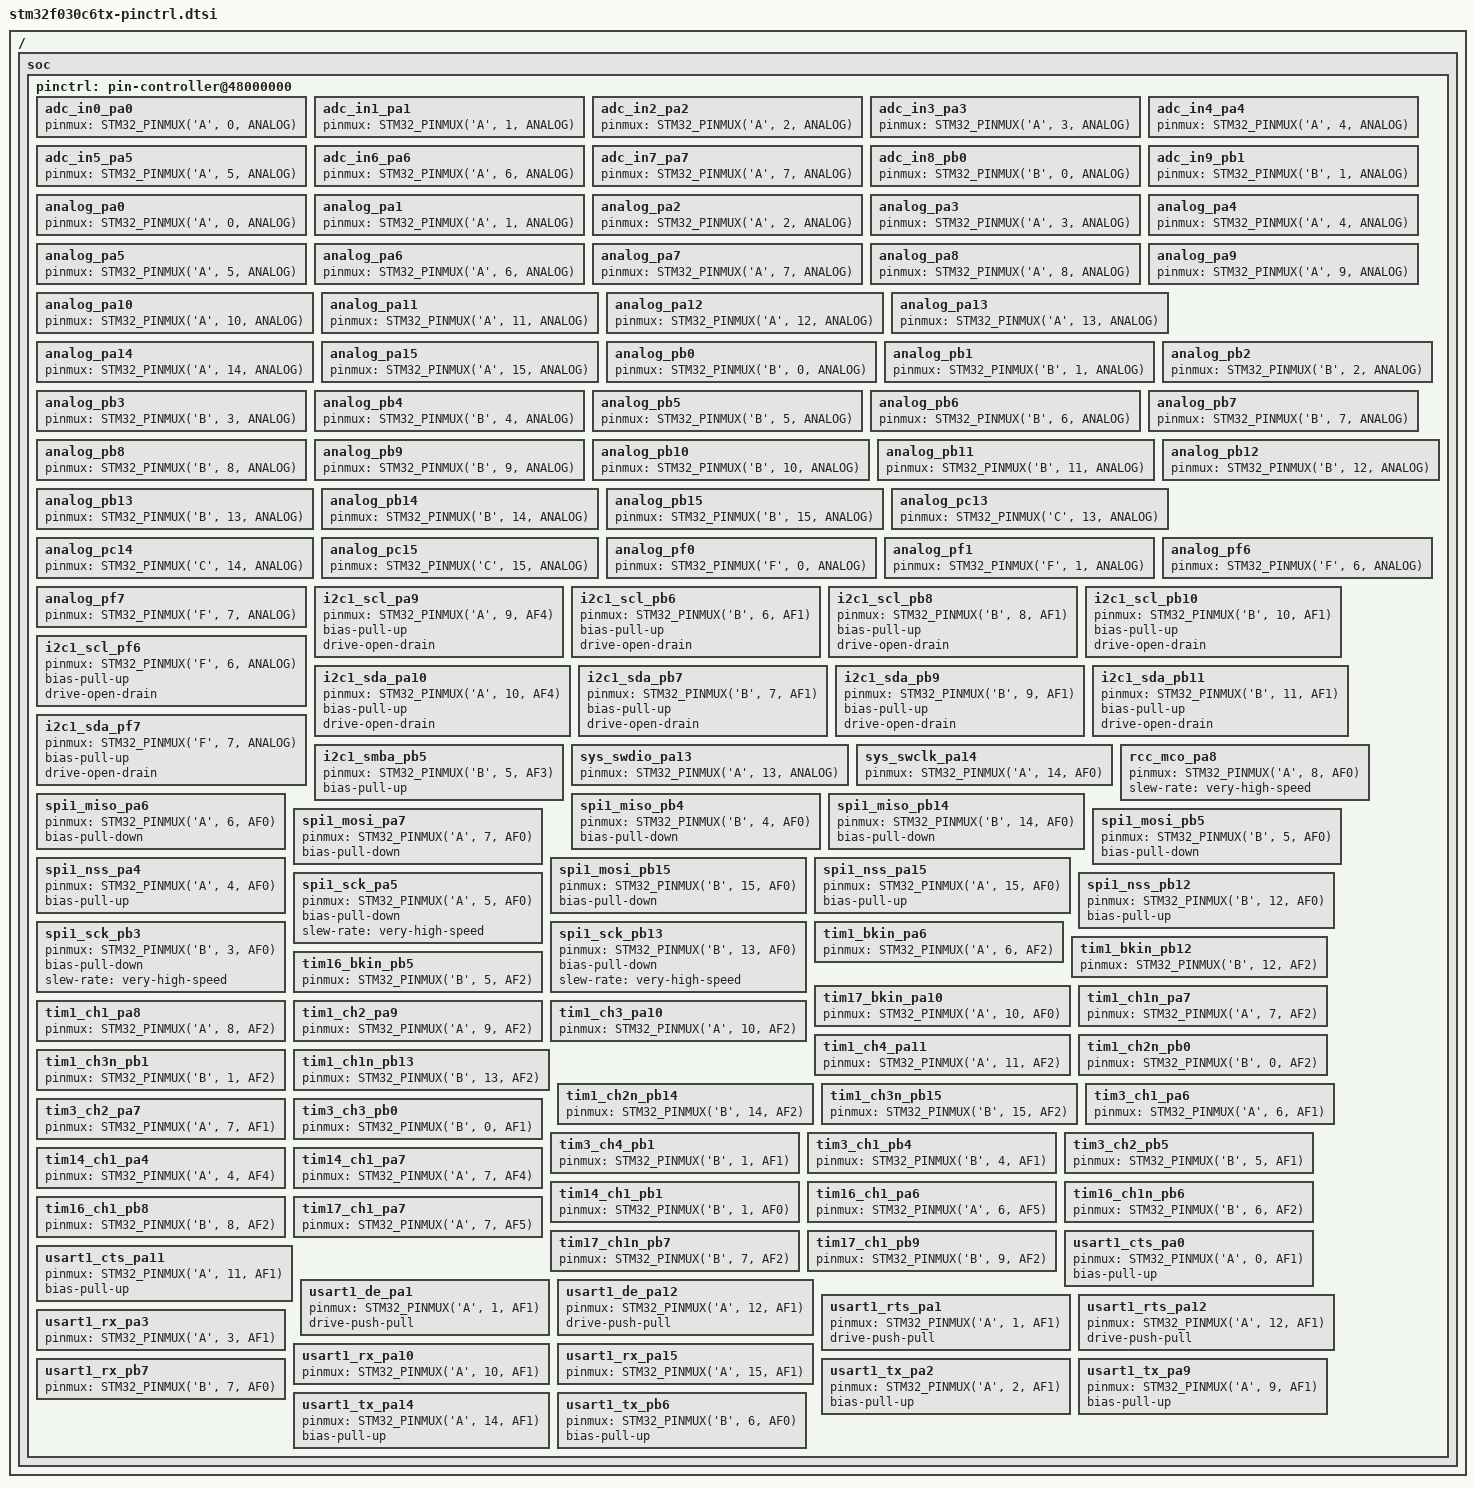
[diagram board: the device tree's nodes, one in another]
/*
 * NOTE: Autogenerated file using genpinctrl.py
 *
 * SPDX-License-Identifier: Apache-2.0
 */

#include <zephyr/dt-bindings/pinctrl/stm32-pinctrl.h>

/ {
	soc {
		pinctrl: pin-controller@48000000 {

			/* ADC_IN / ADC_INN / ADC_INP */

			/omit-if-no-ref/ adc_in0_pa0: adc_in0_pa0 {
				pinmux = <STM32_PINMUX('A', 0, ANALOG)>;
			};

			/omit-if-no-ref/ adc_in1_pa1: adc_in1_pa1 {
				pinmux = <STM32_PINMUX('A', 1, ANALOG)>;
			};

			/omit-if-no-ref/ adc_in2_pa2: adc_in2_pa2 {
				pinmux = <STM32_PINMUX('A', 2, ANALOG)>;
			};

			/omit-if-no-ref/ adc_in3_pa3: adc_in3_pa3 {
				pinmux = <STM32_PINMUX('A', 3, ANALOG)>;
			};

			/omit-if-no-ref/ adc_in4_pa4: adc_in4_pa4 {
				pinmux = <STM32_PINMUX('A', 4, ANALOG)>;
			};

			/omit-if-no-ref/ adc_in5_pa5: adc_in5_pa5 {
				pinmux = <STM32_PINMUX('A', 5, ANALOG)>;
			};

			/omit-if-no-ref/ adc_in6_pa6: adc_in6_pa6 {
				pinmux = <STM32_PINMUX('A', 6, ANALOG)>;
			};

			/omit-if-no-ref/ adc_in7_pa7: adc_in7_pa7 {
				pinmux = <STM32_PINMUX('A', 7, ANALOG)>;
			};

			/omit-if-no-ref/ adc_in8_pb0: adc_in8_pb0 {
				pinmux = <STM32_PINMUX('B', 0, ANALOG)>;
			};

			/omit-if-no-ref/ adc_in9_pb1: adc_in9_pb1 {
				pinmux = <STM32_PINMUX('B', 1, ANALOG)>;
			};

			/* Analog */

			/omit-if-no-ref/ analog_pa0: analog_pa0 {
				pinmux = <STM32_PINMUX('A', 0, ANALOG)>;
			};

			/omit-if-no-ref/ analog_pa1: analog_pa1 {
				pinmux = <STM32_PINMUX('A', 1, ANALOG)>;
			};

			/omit-if-no-ref/ analog_pa2: analog_pa2 {
				pinmux = <STM32_PINMUX('A', 2, ANALOG)>;
			};

			/omit-if-no-ref/ analog_pa3: analog_pa3 {
				pinmux = <STM32_PINMUX('A', 3, ANALOG)>;
			};

			/omit-if-no-ref/ analog_pa4: analog_pa4 {
				pinmux = <STM32_PINMUX('A', 4, ANALOG)>;
			};

			/omit-if-no-ref/ analog_pa5: analog_pa5 {
				pinmux = <STM32_PINMUX('A', 5, ANALOG)>;
			};

			/omit-if-no-ref/ analog_pa6: analog_pa6 {
				pinmux = <STM32_PINMUX('A', 6, ANALOG)>;
			};

			/omit-if-no-ref/ analog_pa7: analog_pa7 {
				pinmux = <STM32_PINMUX('A', 7, ANALOG)>;
			};

			/omit-if-no-ref/ analog_pa8: analog_pa8 {
				pinmux = <STM32_PINMUX('A', 8, ANALOG)>;
			};

			/omit-if-no-ref/ analog_pa9: analog_pa9 {
				pinmux = <STM32_PINMUX('A', 9, ANALOG)>;
			};

			/omit-if-no-ref/ analog_pa10: analog_pa10 {
				pinmux = <STM32_PINMUX('A', 10, ANALOG)>;
			};

			/omit-if-no-ref/ analog_pa11: analog_pa11 {
				pinmux = <STM32_PINMUX('A', 11, ANALOG)>;
			};

			/omit-if-no-ref/ analog_pa12: analog_pa12 {
				pinmux = <STM32_PINMUX('A', 12, ANALOG)>;
			};

			/omit-if-no-ref/ analog_pa13: analog_pa13 {
				pinmux = <STM32_PINMUX('A', 13, ANALOG)>;
			};

			/omit-if-no-ref/ analog_pa14: analog_pa14 {
				pinmux = <STM32_PINMUX('A', 14, ANALOG)>;
			};

			/omit-if-no-ref/ analog_pa15: analog_pa15 {
				pinmux = <STM32_PINMUX('A', 15, ANALOG)>;
			};

			/omit-if-no-ref/ analog_pb0: analog_pb0 {
				pinmux = <STM32_PINMUX('B', 0, ANALOG)>;
			};

			/omit-if-no-ref/ analog_pb1: analog_pb1 {
				pinmux = <STM32_PINMUX('B', 1, ANALOG)>;
			};

			/omit-if-no-ref/ analog_pb2: analog_pb2 {
				pinmux = <STM32_PINMUX('B', 2, ANALOG)>;
			};

			/omit-if-no-ref/ analog_pb3: analog_pb3 {
				pinmux = <STM32_PINMUX('B', 3, ANALOG)>;
			};

			/omit-if-no-ref/ analog_pb4: analog_pb4 {
				pinmux = <STM32_PINMUX('B', 4, ANALOG)>;
			};

			/omit-if-no-ref/ analog_pb5: analog_pb5 {
				pinmux = <STM32_PINMUX('B', 5, ANALOG)>;
			};

			/omit-if-no-ref/ analog_pb6: analog_pb6 {
				pinmux = <STM32_PINMUX('B', 6, ANALOG)>;
			};

			/omit-if-no-ref/ analog_pb7: analog_pb7 {
				pinmux = <STM32_PINMUX('B', 7, ANALOG)>;
			};

			/omit-if-no-ref/ analog_pb8: analog_pb8 {
				pinmux = <STM32_PINMUX('B', 8, ANALOG)>;
			};

			/omit-if-no-ref/ analog_pb9: analog_pb9 {
				pinmux = <STM32_PINMUX('B', 9, ANALOG)>;
			};

			/omit-if-no-ref/ analog_pb10: analog_pb10 {
				pinmux = <STM32_PINMUX('B', 10, ANALOG)>;
			};

			/omit-if-no-ref/ analog_pb11: analog_pb11 {
				pinmux = <STM32_PINMUX('B', 11, ANALOG)>;
			};

			/omit-if-no-ref/ analog_pb12: analog_pb12 {
				pinmux = <STM32_PINMUX('B', 12, ANALOG)>;
			};

			/omit-if-no-ref/ analog_pb13: analog_pb13 {
				pinmux = <STM32_PINMUX('B', 13, ANALOG)>;
			};

			/omit-if-no-ref/ analog_pb14: analog_pb14 {
				pinmux = <STM32_PINMUX('B', 14, ANALOG)>;
			};

			/omit-if-no-ref/ analog_pb15: analog_pb15 {
				pinmux = <STM32_PINMUX('B', 15, ANALOG)>;
			};

			/omit-if-no-ref/ analog_pc13: analog_pc13 {
				pinmux = <STM32_PINMUX('C', 13, ANALOG)>;
			};

			/omit-if-no-ref/ analog_pc14: analog_pc14 {
				pinmux = <STM32_PINMUX('C', 14, ANALOG)>;
			};

			/omit-if-no-ref/ analog_pc15: analog_pc15 {
				pinmux = <STM32_PINMUX('C', 15, ANALOG)>;
			};

			/omit-if-no-ref/ analog_pf0: analog_pf0 {
				pinmux = <STM32_PINMUX('F', 0, ANALOG)>;
			};

			/omit-if-no-ref/ analog_pf1: analog_pf1 {
				pinmux = <STM32_PINMUX('F', 1, ANALOG)>;
			};

			/omit-if-no-ref/ analog_pf6: analog_pf6 {
				pinmux = <STM32_PINMUX('F', 6, ANALOG)>;
			};

			/omit-if-no-ref/ analog_pf7: analog_pf7 {
				pinmux = <STM32_PINMUX('F', 7, ANALOG)>;
			};

			/* I2C_SCL */

			/omit-if-no-ref/ i2c1_scl_pa9: i2c1_scl_pa9 {
				pinmux = <STM32_PINMUX('A', 9, AF4)>;
				bias-pull-up;
				drive-open-drain;
			};

			/omit-if-no-ref/ i2c1_scl_pb6: i2c1_scl_pb6 {
				pinmux = <STM32_PINMUX('B', 6, AF1)>;
				bias-pull-up;
				drive-open-drain;
			};

			/omit-if-no-ref/ i2c1_scl_pb8: i2c1_scl_pb8 {
				pinmux = <STM32_PINMUX('B', 8, AF1)>;
				bias-pull-up;
				drive-open-drain;
			};

			/omit-if-no-ref/ i2c1_scl_pb10: i2c1_scl_pb10 {
				pinmux = <STM32_PINMUX('B', 10, AF1)>;
				bias-pull-up;
				drive-open-drain;
			};

			/omit-if-no-ref/ i2c1_scl_pf6: i2c1_scl_pf6 {
				pinmux = <STM32_PINMUX('F', 6, ANALOG)>;
				bias-pull-up;
				drive-open-drain;
			};

			/* I2C_SDA */

			/omit-if-no-ref/ i2c1_sda_pa10: i2c1_sda_pa10 {
				pinmux = <STM32_PINMUX('A', 10, AF4)>;
				bias-pull-up;
				drive-open-drain;
			};

			/omit-if-no-ref/ i2c1_sda_pb7: i2c1_sda_pb7 {
				pinmux = <STM32_PINMUX('B', 7, AF1)>;
				bias-pull-up;
				drive-open-drain;
			};

			/omit-if-no-ref/ i2c1_sda_pb9: i2c1_sda_pb9 {
				pinmux = <STM32_PINMUX('B', 9, AF1)>;
				bias-pull-up;
				drive-open-drain;
			};

			/omit-if-no-ref/ i2c1_sda_pb11: i2c1_sda_pb11 {
				pinmux = <STM32_PINMUX('B', 11, AF1)>;
				bias-pull-up;
				drive-open-drain;
			};

			/omit-if-no-ref/ i2c1_sda_pf7: i2c1_sda_pf7 {
				pinmux = <STM32_PINMUX('F', 7, ANALOG)>;
				bias-pull-up;
				drive-open-drain;
			};

			/* I2C_SMBA */

			/omit-if-no-ref/ i2c1_smba_pb5: i2c1_smba_pb5 {
				pinmux = <STM32_PINMUX('B', 5, AF3)>;
				bias-pull-up;
			};

			/* JTAG PORT */

			/omit-if-no-ref/ sys_swdio_pa13: sys_swdio_pa13 {
				pinmux = <STM32_PINMUX('A', 13, ANALOG)>;
			};

			/omit-if-no-ref/ sys_swclk_pa14: sys_swclk_pa14 {
				pinmux = <STM32_PINMUX('A', 14, AF0)>;
			};

			/* RCC_MCO */

			/omit-if-no-ref/ rcc_mco_pa8: rcc_mco_pa8 {
				pinmux = <STM32_PINMUX('A', 8, AF0)>;
				slew-rate = "very-high-speed";
			};

			/* SPI_MISO */

			/omit-if-no-ref/ spi1_miso_pa6: spi1_miso_pa6 {
				pinmux = <STM32_PINMUX('A', 6, AF0)>;
				bias-pull-down;
			};

			/omit-if-no-ref/ spi1_miso_pb4: spi1_miso_pb4 {
				pinmux = <STM32_PINMUX('B', 4, AF0)>;
				bias-pull-down;
			};

			/omit-if-no-ref/ spi1_miso_pb14: spi1_miso_pb14 {
				pinmux = <STM32_PINMUX('B', 14, AF0)>;
				bias-pull-down;
			};

			/* SPI_MOSI */

			/omit-if-no-ref/ spi1_mosi_pa7: spi1_mosi_pa7 {
				pinmux = <STM32_PINMUX('A', 7, AF0)>;
				bias-pull-down;
			};

			/omit-if-no-ref/ spi1_mosi_pb5: spi1_mosi_pb5 {
				pinmux = <STM32_PINMUX('B', 5, AF0)>;
				bias-pull-down;
			};

			/omit-if-no-ref/ spi1_mosi_pb15: spi1_mosi_pb15 {
				pinmux = <STM32_PINMUX('B', 15, AF0)>;
				bias-pull-down;
			};

			/* SPI_NSS */

			/omit-if-no-ref/ spi1_nss_pa4: spi1_nss_pa4 {
				pinmux = <STM32_PINMUX('A', 4, AF0)>;
				bias-pull-up;
			};

			/omit-if-no-ref/ spi1_nss_pa15: spi1_nss_pa15 {
				pinmux = <STM32_PINMUX('A', 15, AF0)>;
				bias-pull-up;
			};

			/omit-if-no-ref/ spi1_nss_pb12: spi1_nss_pb12 {
				pinmux = <STM32_PINMUX('B', 12, AF0)>;
				bias-pull-up;
			};

			/* SPI_SCK */

			/omit-if-no-ref/ spi1_sck_pa5: spi1_sck_pa5 {
				pinmux = <STM32_PINMUX('A', 5, AF0)>;
				bias-pull-down;
				slew-rate = "very-high-speed";
			};

			/omit-if-no-ref/ spi1_sck_pb3: spi1_sck_pb3 {
				pinmux = <STM32_PINMUX('B', 3, AF0)>;
				bias-pull-down;
				slew-rate = "very-high-speed";
			};

			/omit-if-no-ref/ spi1_sck_pb13: spi1_sck_pb13 {
				pinmux = <STM32_PINMUX('B', 13, AF0)>;
				bias-pull-down;
				slew-rate = "very-high-speed";
			};

			/* TIM_BKIN */

			/omit-if-no-ref/ tim1_bkin_pa6: tim1_bkin_pa6 {
				pinmux = <STM32_PINMUX('A', 6, AF2)>;
			};

			/omit-if-no-ref/ tim1_bkin_pb12: tim1_bkin_pb12 {
				pinmux = <STM32_PINMUX('B', 12, AF2)>;
			};

			/omit-if-no-ref/ tim16_bkin_pb5: tim16_bkin_pb5 {
				pinmux = <STM32_PINMUX('B', 5, AF2)>;
			};

			/omit-if-no-ref/ tim17_bkin_pa10: tim17_bkin_pa10 {
				pinmux = <STM32_PINMUX('A', 10, AF0)>;
			};

			/* TIM_CH / TIM_CHN */

			/omit-if-no-ref/ tim1_ch1n_pa7: tim1_ch1n_pa7 {
				pinmux = <STM32_PINMUX('A', 7, AF2)>;
			};

			/omit-if-no-ref/ tim1_ch1_pa8: tim1_ch1_pa8 {
				pinmux = <STM32_PINMUX('A', 8, AF2)>;
			};

			/omit-if-no-ref/ tim1_ch2_pa9: tim1_ch2_pa9 {
				pinmux = <STM32_PINMUX('A', 9, AF2)>;
			};

			/omit-if-no-ref/ tim1_ch3_pa10: tim1_ch3_pa10 {
				pinmux = <STM32_PINMUX('A', 10, AF2)>;
			};

			/omit-if-no-ref/ tim1_ch4_pa11: tim1_ch4_pa11 {
				pinmux = <STM32_PINMUX('A', 11, AF2)>;
			};

			/omit-if-no-ref/ tim1_ch2n_pb0: tim1_ch2n_pb0 {
				pinmux = <STM32_PINMUX('B', 0, AF2)>;
			};

			/omit-if-no-ref/ tim1_ch3n_pb1: tim1_ch3n_pb1 {
				pinmux = <STM32_PINMUX('B', 1, AF2)>;
			};

			/omit-if-no-ref/ tim1_ch1n_pb13: tim1_ch1n_pb13 {
				pinmux = <STM32_PINMUX('B', 13, AF2)>;
			};

			/omit-if-no-ref/ tim1_ch2n_pb14: tim1_ch2n_pb14 {
				pinmux = <STM32_PINMUX('B', 14, AF2)>;
			};

			/omit-if-no-ref/ tim1_ch3n_pb15: tim1_ch3n_pb15 {
				pinmux = <STM32_PINMUX('B', 15, AF2)>;
			};

			/omit-if-no-ref/ tim3_ch1_pa6: tim3_ch1_pa6 {
				pinmux = <STM32_PINMUX('A', 6, AF1)>;
			};

			/omit-if-no-ref/ tim3_ch2_pa7: tim3_ch2_pa7 {
				pinmux = <STM32_PINMUX('A', 7, AF1)>;
			};

			/omit-if-no-ref/ tim3_ch3_pb0: tim3_ch3_pb0 {
				pinmux = <STM32_PINMUX('B', 0, AF1)>;
			};

			/omit-if-no-ref/ tim3_ch4_pb1: tim3_ch4_pb1 {
				pinmux = <STM32_PINMUX('B', 1, AF1)>;
			};

			/omit-if-no-ref/ tim3_ch1_pb4: tim3_ch1_pb4 {
				pinmux = <STM32_PINMUX('B', 4, AF1)>;
			};

			/omit-if-no-ref/ tim3_ch2_pb5: tim3_ch2_pb5 {
				pinmux = <STM32_PINMUX('B', 5, AF1)>;
			};

			/omit-if-no-ref/ tim14_ch1_pa4: tim14_ch1_pa4 {
				pinmux = <STM32_PINMUX('A', 4, AF4)>;
			};

			/omit-if-no-ref/ tim14_ch1_pa7: tim14_ch1_pa7 {
				pinmux = <STM32_PINMUX('A', 7, AF4)>;
			};

			/omit-if-no-ref/ tim14_ch1_pb1: tim14_ch1_pb1 {
				pinmux = <STM32_PINMUX('B', 1, AF0)>;
			};

			/omit-if-no-ref/ tim16_ch1_pa6: tim16_ch1_pa6 {
				pinmux = <STM32_PINMUX('A', 6, AF5)>;
			};

			/omit-if-no-ref/ tim16_ch1n_pb6: tim16_ch1n_pb6 {
				pinmux = <STM32_PINMUX('B', 6, AF2)>;
			};

			/omit-if-no-ref/ tim16_ch1_pb8: tim16_ch1_pb8 {
				pinmux = <STM32_PINMUX('B', 8, AF2)>;
			};

			/omit-if-no-ref/ tim17_ch1_pa7: tim17_ch1_pa7 {
				pinmux = <STM32_PINMUX('A', 7, AF5)>;
			};

			/omit-if-no-ref/ tim17_ch1n_pb7: tim17_ch1n_pb7 {
				pinmux = <STM32_PINMUX('B', 7, AF2)>;
			};

			/omit-if-no-ref/ tim17_ch1_pb9: tim17_ch1_pb9 {
				pinmux = <STM32_PINMUX('B', 9, AF2)>;
			};

			/* UART_CTS / USART_CTS / LPUART_CTS */

			/omit-if-no-ref/ usart1_cts_pa0: usart1_cts_pa0 {
				pinmux = <STM32_PINMUX('A', 0, AF1)>;
				bias-pull-up;
			};

			/omit-if-no-ref/ usart1_cts_pa11: usart1_cts_pa11 {
				pinmux = <STM32_PINMUX('A', 11, AF1)>;
				bias-pull-up;
			};

			/* UART_DE / USART_DE / LPUART_DE */

			/omit-if-no-ref/ usart1_de_pa1: usart1_de_pa1 {
				pinmux = <STM32_PINMUX('A', 1, AF1)>;
				drive-push-pull;
			};

			/omit-if-no-ref/ usart1_de_pa12: usart1_de_pa12 {
				pinmux = <STM32_PINMUX('A', 12, AF1)>;
				drive-push-pull;
			};

			/* UART_RTS / USART_RTS / LPUART_RTS */

			/omit-if-no-ref/ usart1_rts_pa1: usart1_rts_pa1 {
				pinmux = <STM32_PINMUX('A', 1, AF1)>;
				drive-push-pull;
			};

			/omit-if-no-ref/ usart1_rts_pa12: usart1_rts_pa12 {
				pinmux = <STM32_PINMUX('A', 12, AF1)>;
				drive-push-pull;
			};

			/* UART_RX / USART_RX / LPUART_RX */

			/omit-if-no-ref/ usart1_rx_pa3: usart1_rx_pa3 {
				pinmux = <STM32_PINMUX('A', 3, AF1)>;
			};

			/omit-if-no-ref/ usart1_rx_pa10: usart1_rx_pa10 {
				pinmux = <STM32_PINMUX('A', 10, AF1)>;
			};

			/omit-if-no-ref/ usart1_rx_pa15: usart1_rx_pa15 {
				pinmux = <STM32_PINMUX('A', 15, AF1)>;
			};

			/omit-if-no-ref/ usart1_rx_pb7: usart1_rx_pb7 {
				pinmux = <STM32_PINMUX('B', 7, AF0)>;
			};

			/* UART_TX / USART_TX / LPUART_TX */

			/omit-if-no-ref/ usart1_tx_pa2: usart1_tx_pa2 {
				pinmux = <STM32_PINMUX('A', 2, AF1)>;
				bias-pull-up;
			};

			/omit-if-no-ref/ usart1_tx_pa9: usart1_tx_pa9 {
				pinmux = <STM32_PINMUX('A', 9, AF1)>;
				bias-pull-up;
			};

			/omit-if-no-ref/ usart1_tx_pa14: usart1_tx_pa14 {
				pinmux = <STM32_PINMUX('A', 14, AF1)>;
				bias-pull-up;
			};

			/omit-if-no-ref/ usart1_tx_pb6: usart1_tx_pb6 {
				pinmux = <STM32_PINMUX('B', 6, AF0)>;
				bias-pull-up;
			};

		};
	};
};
